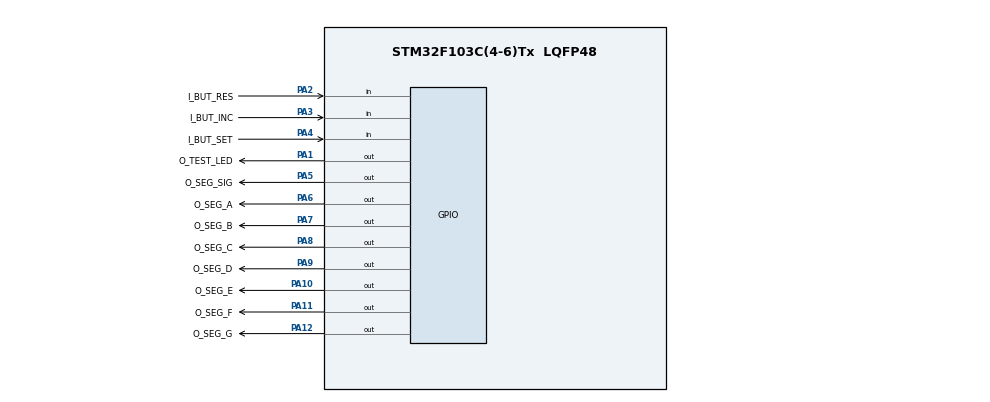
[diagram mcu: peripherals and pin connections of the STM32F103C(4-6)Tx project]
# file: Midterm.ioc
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Mcu.Family=STM32F1
Mcu.Name=STM32F103C(4-6)Tx
Mcu.Package=LQFP48
NVIC.PriorityGroup=NVIC_PRIORITYGROUP_4
NVIC.TIM2_IRQn=true\:0\:0\:false\:false\:true\:true\:true\:true
PA1.GPIO_Label=O_TEST_LED
PA1.Signal=GPIO_Output
PA10.GPIO_Label=O_SEG_E
PA10.Signal=GPIO_Output
PA11.GPIO_Label=O_SEG_F
PA11.Signal=GPIO_Output
PA12.GPIO_Label=O_SEG_G
PA12.Signal=GPIO_Output
PA13.Mode=Serial_Wire
PA13.Signal=SYS_JTMS-SWDIO
PA14.Mode=Serial_Wire
PA14.Signal=SYS_JTCK-SWCLK
PA2.GPIO_Label=I_BUT_RES
PA2.Signal=GPIO_Input
PA3.GPIO_Label=I_BUT_INC
PA3.Signal=GPIO_Input
PA4.GPIO_Label=I_BUT_SET
PA4.Signal=GPIO_Input
PA5.GPIO_Label=O_SEG_SIG
PA5.Signal=GPIO_Output
PA6.GPIO_Label=O_SEG_A
PA6.Signal=GPIO_Output
PA7.GPIO_Label=O_SEG_B
PA7.Signal=GPIO_Output
PA8.GPIO_Label=O_SEG_C
PA8.Signal=GPIO_Output
PA9.GPIO_Label=O_SEG_D
PA9.Signal=GPIO_Output
ProjectManager.HeapSize=0x200
ProjectManager.StackSize=0x400
ProjectManager.TargetToolchain=STM32CubeIDE
RCC.APB1Freq_Value=8000000
RCC.APB2Freq_Value=8000000
TIM2.Period=9
TIM2.Prescaler=7999
VP_TIM2_VS_ClockSourceINT.Mode=Internal
board=custom

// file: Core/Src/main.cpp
/* USER CODE BEGIN Header */
/**
 ******************************************************************************
 * @file           : main.c
 * @brief          : Main program body
 ******************************************************************************
 * @attention
 *
 * Copyright (c) 2022 STMicroelectronics.
 * All rights reserved.
 *
 * This software is licensed under terms that can be found in the LICENSE file
 * in the root directory of this software component.
 * If no LICENSE file comes with this software, it is provided AS-IS.
 *
 ******************************************************************************
 */
/* USER CODE END Header */
#include "main.h"

#include "global.h"

TIM_HandleTypeDef htim2;

void SystemClock_Config(void);
static void MX_GPIO_Init(void);
static void MX_TIM2_Init(void);
void HAL_TIM_PeriodElapsedCallback(TIM_HandleTypeDef* htim);

int main(void)
{

    /* MCU Configuration--------------------------------------------------------*/

    /* Reset of all peripherals, Initializes the Flash interface and the Systick.
     */
    HAL_Init();

    /* Configure the system clock */
    SystemClock_Config();

    /* Initialize all configured peripherals */
    MX_TIM2_Init();
    MX_GPIO_Init();
    /* USER CODE BEGIN 2 */
    HAL_TIM_Base_Start_IT(&htim2);

    /*
     * Initialize timers here
     */
    /* USER CODE END 2 */

    /* Infinite loop */
    while (1) {

        /* USER CODE BEGIN 3 */
        g_LedService.Run();
        g_Controller.Run();
    }
    /* USER CODE END 3 */
}

/*
 * Callback, calls every 10ms
 */
void HAL_TIM_PeriodElapsedCallback(TIM_HandleTypeDef* htim)
{
    /*
     * Button listeners
     */
    g_ButtonRes.Listen();
    g_ButtonInc.Listen();
    g_ButtonDec.Listen();

    /*
     * Timer breathers
     */
    g_TimerGlobal.Breath();
    g_TimerTestLed.Breath();
    g_TimerAutoDecrement.Breath();
}

void SystemClock_Config(void)
{
    RCC_OscInitTypeDef RCC_OscInitStruct = { 0 };
    RCC_ClkInitTypeDef RCC_ClkInitStruct = { 0 };

    /** Initializes the RCC Oscillators according to the specified parameters
     * in the RCC_OscInitTypeDef structure.
     */
    RCC_OscInitStruct.OscillatorType = RCC_OSCILLATORTYPE_HSI;
    RCC_OscInitStruct.HSIState = RCC_HSI_ON;
    RCC_OscInitStruct.HSICalibrationValue = RCC_HSICALIBRATION_DEFAULT;
    RCC_OscInitStruct.PLL.PLLState = RCC_PLL_NONE;
    if (HAL_RCC_OscConfig(&RCC_OscInitStruct) != HAL_OK) {
        Error_Handler();
    }

    /** Initializes the CPU, AHB and APB buses clocks
     */
    RCC_ClkInitStruct.ClockType = RCC_CLOCKTYPE_HCLK | RCC_CLOCKTYPE_SYSCLK
        | RCC_CLOCKTYPE_PCLK1 | RCC_CLOCKTYPE_PCLK2;
    RCC_ClkInitStruct.SYSCLKSource = RCC_SYSCLKSOURCE_HSI;
    RCC_ClkInitStruct.AHBCLKDivider = RCC_SYSCLK_DIV1;
    RCC_ClkInitStruct.APB1CLKDivider = RCC_HCLK_DIV1;
    RCC_ClkInitStruct.APB2CLKDivider = RCC_HCLK_DIV1;

    if (HAL_RCC_ClockConfig(&RCC_ClkInitStruct, FLASH_LATENCY_0) != HAL_OK) {
        Error_Handler();
    }
}

static void MX_TIM2_Init(void)
{

    TIM_ClockConfigTypeDef sClockSourceConfig = { 0 };
    TIM_MasterConfigTypeDef sMasterConfig = { 0 };

    htim2.Instance = TIM2;
    htim2.Init.Prescaler = 7999;
    htim2.Init.CounterMode = TIM_COUNTERMODE_UP;
    htim2.Init.Period = 9;
    htim2.Init.ClockDivision = TIM_CLOCKDIVISION_DIV1;
    htim2.Init.AutoReloadPreload = TIM_AUTORELOAD_PRELOAD_DISABLE;
    if (HAL_TIM_Base_Init(&htim2) != HAL_OK) {
        Error_Handler();
    }
    sClockSourceConfig.ClockSource = TIM_CLOCKSOURCE_INTERNAL;
    if (HAL_TIM_ConfigClockSource(&htim2, &sClockSourceConfig) != HAL_OK) {
        Error_Handler();
    }
    sMasterConfig.MasterOutputTrigger = TIM_TRGO_RESET;
    sMasterConfig.MasterSlaveMode = TIM_MASTERSLAVEMODE_DISABLE;
    if (HAL_TIMEx_MasterConfigSynchronization(&htim2, &sMasterConfig) != HAL_OK) {
        Error_Handler();
    }
}

static void MX_GPIO_Init(void)
{
    GPIO_InitTypeDef GPIO_InitStruct = { 0 };

    /* GPIO Ports Clock Enable */
    __HAL_RCC_GPIOA_CLK_ENABLE();

    /*Configure GPIO pin Output Level */
    HAL_GPIO_WritePin(GPIOA, O_TEST_LED_Pin | O_SEG_SIG_Pin | O_SEG_A_Pin | O_SEG_B_Pin | O_SEG_C_Pin | O_SEG_D_Pin | O_SEG_E_Pin | O_SEG_F_Pin | O_SEG_G_Pin, GPIO_PIN_RESET);

    /*Configure GPIO pins : O_TEST_LED_Pin O_SEG_SIG_Pin O_SEG_A_Pin O_SEG_B_Pin
                             O_SEG_C_Pin O_SEG_D_Pin O_SEG_E_Pin O_SEG_F_Pin
                             O_SEG_G_Pin */
    GPIO_InitStruct.Pin = O_TEST_LED_Pin | O_SEG_SIG_Pin | O_SEG_A_Pin | O_SEG_B_Pin
        | O_SEG_C_Pin | O_SEG_D_Pin | O_SEG_E_Pin | O_SEG_F_Pin
        | O_SEG_G_Pin;
    GPIO_InitStruct.Mode = GPIO_MODE_OUTPUT_PP;
    GPIO_InitStruct.Pull = GPIO_NOPULL;
    GPIO_InitStruct.Speed = GPIO_SPEED_FREQ_LOW;
    HAL_GPIO_Init(GPIOA, &GPIO_InitStruct);

    /*Configure GPIO pins : I_BUT_RES_Pin I_BUT_INC_Pin I_BUT_SET_Pin */
    GPIO_InitStruct.Pin = I_BUT_RES_Pin | I_BUT_INC_Pin | I_BUT_SET_Pin;
    GPIO_InitStruct.Mode = GPIO_MODE_INPUT;
    GPIO_InitStruct.Pull = GPIO_NOPULL;
    HAL_GPIO_Init(GPIOA, &GPIO_InitStruct);
}

void Error_Handler(void)
{
    __disable_irq();
    while (1) {
    }
}
